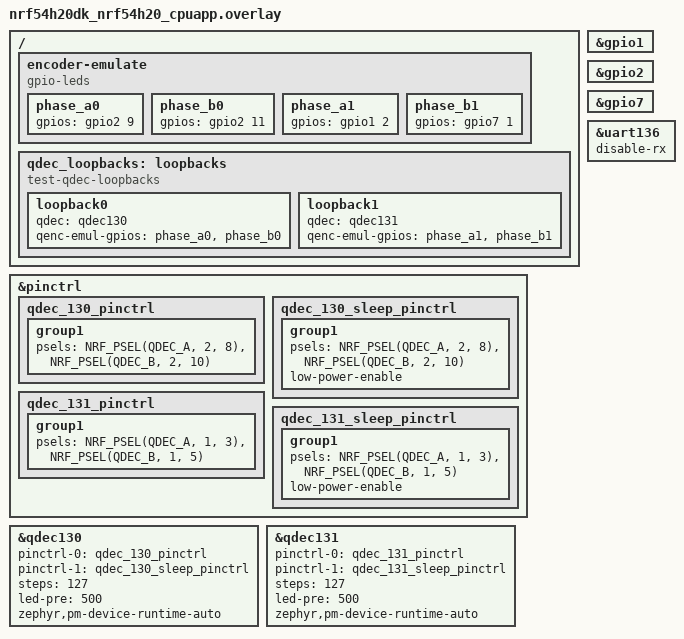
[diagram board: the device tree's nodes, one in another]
/*
 * Copyright 2024 Nordic Semiconductor ASA
 * SPDX-License-Identifier: Apache-2.0
 */

/* Required loopbacks
 * P2.08 <-> P2.09
 * P2.10 <-> P2.11
 * P1.02 <-> P1.03
 * P7.01 <-> P1.05
 */

/ {
	encoder-emulate {
		compatible = "gpio-leds";
		phase_a0: phase_a0 {
			gpios = <&gpio2 9 GPIO_ACTIVE_HIGH>;
		};
		phase_b0: phase_b0 {
			gpios = <&gpio2 11 GPIO_ACTIVE_HIGH>;
		};
		phase_a1: phase_a1 {
			gpios = <&gpio1 2 GPIO_ACTIVE_HIGH>;
		};
		phase_b1: phase_b1 {
			gpios = <&gpio7 1 GPIO_ACTIVE_HIGH>;
		};
	};

	qdec_loopbacks: loopbacks {
		compatible = "test-qdec-loopbacks";
		loopback0 {
			qdec = <&qdec130>;
			qenc-emul-gpios = <&phase_a0 &phase_b0>;
		};
		loopback1 {
			qdec = <&qdec131>;
			qenc-emul-gpios = <&phase_a1 &phase_b1>;
		};
	};
};

&pinctrl {
	qdec_130_pinctrl: qdec_130_pinctrl {
		group1 {
			psels = <NRF_PSEL(QDEC_A, 2, 8)>,
				<NRF_PSEL(QDEC_B, 2, 10)>;
		};
	};

	qdec_130_sleep_pinctrl: qdec_130_sleep_pinctrl {
		group1 {
			psels = <NRF_PSEL(QDEC_A, 2, 8)>,
				<NRF_PSEL(QDEC_B, 2, 10)>;
			low-power-enable;
		};
	};

	qdec_131_pinctrl: qdec_131_pinctrl {
		group1 {
			psels = <NRF_PSEL(QDEC_A, 1, 3)>,
				<NRF_PSEL(QDEC_B, 1, 5)>;
		};
	};

	qdec_131_sleep_pinctrl: qdec_131_sleep_pinctrl {
		group1 {
			psels = <NRF_PSEL(QDEC_A, 1, 3)>,
				<NRF_PSEL(QDEC_B, 1, 5)>;
			low-power-enable;
		};
	};
};

&gpio1 {
	status = "okay";
};

&gpio2 {
	status = "okay";
};

&gpio7 {
	status = "okay";
};

&qdec130 {
	status = "okay";
	pinctrl-0 = <&qdec_130_pinctrl>;
	pinctrl-1 = <&qdec_130_sleep_pinctrl>;
	pinctrl-names = "default", "sleep";
	steps = <127>;
	led-pre = <500>;
	zephyr,pm-device-runtime-auto;
};

&qdec131 {
	status = "okay";
	pinctrl-0 = <&qdec_131_pinctrl>;
	pinctrl-1 = <&qdec_131_sleep_pinctrl>;
	pinctrl-names = "default", "sleep";
	steps = <127>;
	led-pre = <500>;
	zephyr,pm-device-runtime-auto;
};

/* To prevent enabling console receiver. */
&uart136 {
	disable-rx;
};
